AUTOSAR XML (schema 00052)
package /apd/Executables
  executable controller: category=APPLICATION_LEVEL, build-type=BUILD-TYPE-DEBUG, minimum-timer-granularity=1000.0, reporting-behavior=REPORTS-EXECUTION-STATE, version=0.1.0
    root sw component prototype ControllerRoot: application-type=controller
package /apd/AdaptiveApplicationSwComponentTypes
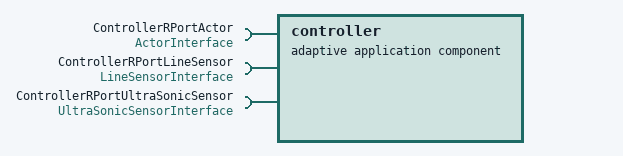
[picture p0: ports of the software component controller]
  adaptive application sw component type controller
    require port ControllerRPortActor: required-interface=ActorInterface
    require port ControllerRPortLineSensor: required-interface=LineSensorInterface
    require port ControllerRPortUltraSonicSensor: required-interface=UltraSonicSensorInterface
